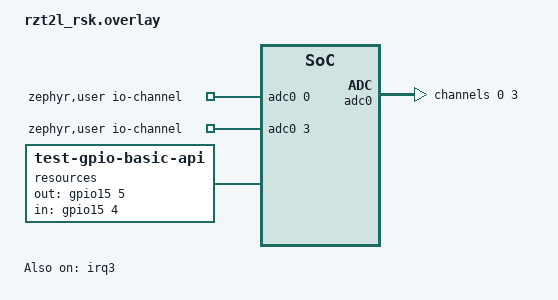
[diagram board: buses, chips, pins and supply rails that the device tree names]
/*
 * Copyright (c) 2025 Renesas Electronics Corporation
 *
 * SPDX-License-Identifier: Apache-2.0
 */

/ {
	zephyr,user {
		io-channels = <&adc0 0>, <&adc0 3>;
	};
};

&adc0 {
	status = "okay";
	#address-cells = <1>;
	#size-cells = <0>;

	channel@0 {
		reg = <0>;
		zephyr,gain = "ADC_GAIN_1";
		zephyr,reference = "ADC_REF_INTERNAL";
		zephyr,resolution = <12>;
		zephyr,acquisition-time = <ADC_ACQ_TIME_DEFAULT>;
		zephyr,vref-mv = <1800>;
	};

	channel@3 {
		reg = <3>;
		zephyr,gain = "ADC_GAIN_1";
		zephyr,reference = "ADC_REF_INTERNAL";
		zephyr,resolution = <12>;
		zephyr,acquisition-time = <ADC_ACQ_TIME_DEFAULT>;
		zephyr,vref-mv = <1800>;
	};
};

/ {
	resources {
		compatible = "test-gpio-basic-api";
		out-gpios = <&gpio15 5 GPIO_ACTIVE_HIGH>;
		in-gpios = <&gpio15 4 GPIO_ACTIVE_HIGH>;
	};
};

&pinctrl {
	input_test: input_test {
		group1 {
			pinmux = <RZT_PINMUX(PORT_15, 4, 4)>;
			input-enable;
		};
	};
};

&irq3 {
	trigger-type = "falling";
	pinctrl-0 = <&input_test>;
	pinctrl-names = "default";
	status = "okay";
};

&gpio15 {
	irqs = <&irq3 4>;
	status = "okay";
};
